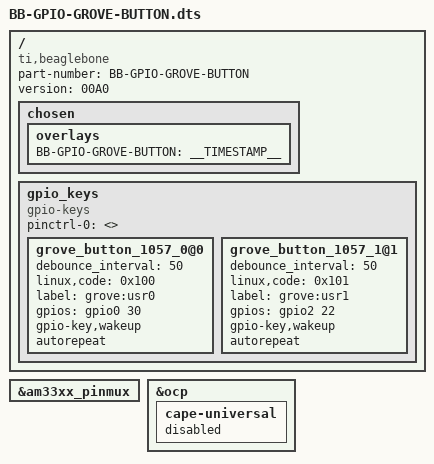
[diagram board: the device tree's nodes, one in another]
/*
 * Copyright (C) 2012 Seeed Studio
 * Peter Yang <turmary@126.com>
 *
 * MIT License
 *
 */
/dts-v1/;
/plugin/;

#include <dt-bindings/board/am335x-bbw-bbb-base.h>
#include <dt-bindings/gpio/gpio.h>
#include <dt-bindings/pinctrl/am33xx.h>

/ {
	compatible = "ti,beaglebone", "ti,beaglebone-black", "ti,beaglebone-green";

	/* identification */
	part-number = "BB-GPIO-GROVE-BUTTON";
	version = "00A0";
	/*
	 * Helper to show loaded overlays under: /proc/device-tree/chosen/overlays/
	 */
	fragment@0 {
		target-path="/";
		__overlay__ {

			chosen {
				overlays {
					BB-GPIO-GROVE-BUTTON = __TIMESTAMP__;
				};
			};
		};
	};

	fragment@1 {
		target = <&am33xx_pinmux>;
		__overlay__ {
			/* already defined by main dtb (am335x-pocketbeagle.dtb) */
			#if 0
			grove_button_1057_pins: pinmux_grove_button_1057_pins {
				pinctrl-single,pins = <
					/* slot 1057 */
					AM33XX_IOPAD(0x0864, PIN_INPUT | MUX_MODE7)		/* gpmc_a9.gpio1_25 */
					AM33XX_IOPAD(0x0868, PIN_INPUT | MUX_MODE7)		/* gpmc_a10.gpio1_26 */
				>;
			};

			grove_button_1059_pins: pinmux_grove_button_1059_pins {
				pinctrl-single,pins = <
					/* slot 1059 */
					AM33XX_IOPAD(0x086c, PIN_INPUT | MUX_MODE7)		/* gpmc_a11.gpio1_27 */
					AM33XX_IOPAD(0x0878, PIN_INPUT | MUX_MODE7)		/* gpmc_be1n.gpio1_28 */
				>;
			};

			grove_button_pwm_pins: pinmux_grove_button_pwm_pins {
				pinctrl-single,pins = <
					/* slot PWM */
					AM33XX_IOPAD(0x0990, PIN_INPUT | MUX_MODE7)		/* mcasp0_aclkx.gpio3_14 */
					AM33XX_IOPAD(0x0848, PIN_INPUT | MUX_MODE7)		/* gpmc_a2.gpio1_18 */
				>;
			};

			grove_button_uart4_pins: pinmux_grove_button_uart4_pins {
				pinctrl-single,pins = <
					/* slot UART4 */
					AM33XX_IOPAD(0x0870, PIN_INPUT | MUX_MODE7)		/* gpmc_wait0.gpio0_30 */
					AM33XX_IOPAD(0x0874, PIN_INPUT | MUX_MODE7)		/* gpmc_wpn.gpio0_31 */
				>;
			};
			#endif
		};
	};

	fragment@10 {
		target= <&ocp>;
		__overlay__ {
			cape-universal {
				status = "disabled";
			};
		};
	};

	fragment@20 {
		target-path="/";
		__overlay__ {

			gpio_keys {
				compatible = "gpio-keys";
				pinctrl-names = "default";
				pinctrl-0 = <>;

				#address-cells = <1>;
				#size-cells = <0>;

				grove_button_1057_0@0 {
					debounce_interval = <50>;
					linux,code = <0x100>;
					label = "grove:usr0";
					/* Grove Button, HIGH valid/press */
					gpios = <&gpio0 30 0x0>;
					gpio-key,wakeup;
					autorepeat;
				};

				grove_button_1057_1@1 {
					debounce_interval = <50>;
					linux,code = <0x101>;
					label = "grove:usr1";
					/*
					 * Grove Red/Yellow/Blue LED Button
					 * LOW valid/press
					 */
					gpios = <&gpio2 22 0x0>;
					gpio-key,wakeup;
					autorepeat;
				};

				/*
				 * Only SLOT 1057 enabled, uncomment below statements
				 * if you need other slots be used.
				 */
				#if 0
				grove_button_1059_0@2 {
					debounce_interval = <50>;
					linux,code = <0x102>;
					label = "grove:usr2";
					gpios = <&gpio1 27 0x0>;
					gpio-key,wakeup;
					autorepeat;
				};
				grove_button_1059_1@2 {
					debounce_interval = <50>;
					linux,code = <0x103>;
					label = "grove:usr3";
					gpios = <&gpio1 28 0x1>;
					gpio-key,wakeup;
					autorepeat;
				};

				grove_button_pwm_0@4 {
					debounce_interval = <50>;
					linux,code = <0x104>;
					label = "grove:usr4";
					gpios = <&gpio3 14 0x0>;
					gpio-key,wakeup;
					autorepeat;
				};
				grove_button_pwm_1@5 {
					debounce_interval = <50>;
					linux,code = <0x105>;
					label = "grove:usr5";
					gpios = <&gpio1 18 0x1>;
					gpio-key,wakeup;
					autorepeat;
				};

				grove_button_uart4_0@6 {
					debounce_interval = <50>;
					linux,code = <0x106>;
					label = "grove:usr6";
					gpios = <&gpio0 30 0x0>;
					gpio-key,wakeup;
					autorepeat;
				};
				grove_button_uart4_1@7 {
					debounce_interval = <50>;
					linux,code = <0x107>;
					label = "grove:usr7";
					gpios = <&gpio0 31 0x1>;
					gpio-key,wakeup;
					autorepeat;
				};
				#endif
			};
		};
	};
};
